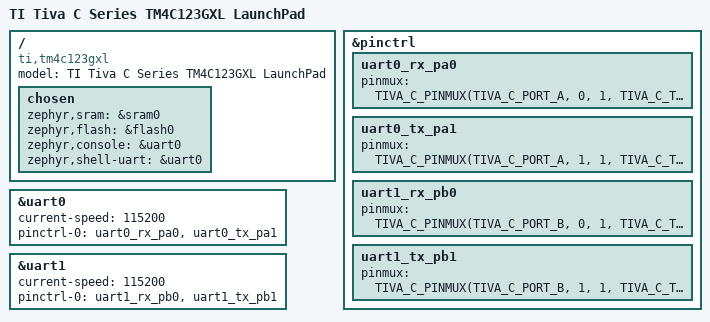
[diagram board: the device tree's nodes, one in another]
/*
 * SPDX-License-Identifier: Apache-2.0
 *
 * Copyright (c) 2026 Linumiz
 * Author: Sri Surya <srisurya@linumiz.com>
 */

/dts-v1/;

#include <ti/tm4c123gh6pm.dtsi>
#include <dt-bindings/pinctrl/tiva-c-pinctrl.h>

/*
 * Pin configuration nodes for UART0 and UART1.
 * Use TIVA_C_PINMUX(port, pin, mux, type) macro.
 */
&pinctrl {
	uart0_rx_pa0: uart0_rx_pa0 {
		pinmux = <TIVA_C_PINMUX(TIVA_C_PORT_A, 0, 1, TIVA_C_TYPE_UART)>;
	};
	uart0_tx_pa1: uart0_tx_pa1 {
		pinmux = <TIVA_C_PINMUX(TIVA_C_PORT_A, 1, 1, TIVA_C_TYPE_UART)>;
	};
	uart1_rx_pb0: uart1_rx_pb0 {
		pinmux = <TIVA_C_PINMUX(TIVA_C_PORT_B, 0, 1, TIVA_C_TYPE_UART)>;
	};
	uart1_tx_pb1: uart1_tx_pb1 {
		pinmux = <TIVA_C_PINMUX(TIVA_C_PORT_B, 1, 1, TIVA_C_TYPE_UART)>;
	};
};

/ {
	model = "TI Tiva C Series TM4C123GXL LaunchPad";
	compatible = "ti,tm4c123gxl";

	chosen {
		zephyr,sram = &sram0;
		zephyr,flash = &flash0;
		zephyr,console = &uart0;
		zephyr,shell-uart = &uart0;
	};
};

/* UART0 is connected to the on-board ICDI virtual COM port (PA0/PA1) */
&uart0 {
	status = "okay";
	current-speed = <115200>;
	pinctrl-0 = <&uart0_rx_pa0 &uart0_tx_pa1>;
	pinctrl-names = "default";
};

/* UART1 on header pins PB0/PB1 */
&uart1 {
	status = "okay";
	current-speed = <115200>;
	pinctrl-0 = <&uart1_rx_pb0 &uart1_tx_pb1>;
	pinctrl-names = "default";
};
